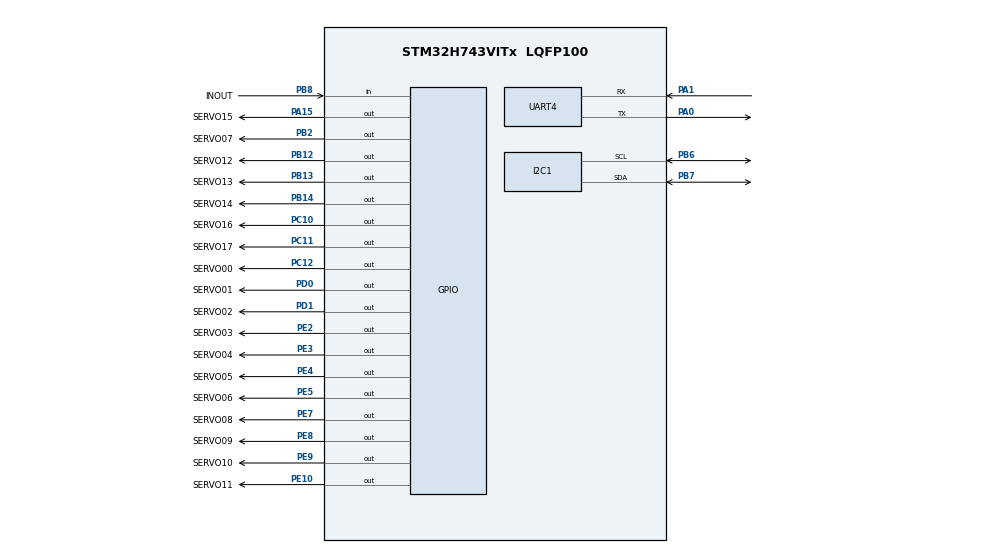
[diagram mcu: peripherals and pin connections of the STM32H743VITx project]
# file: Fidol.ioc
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Dma.Request0=UART4_RX
Dma.Request1=UART4_TX
Dma.UART4_RX.0.Direction=DMA_PERIPH_TO_MEMORY
Dma.UART4_RX.0.EventEnable=DISABLE
Dma.UART4_RX.0.FIFOMode=DMA_FIFOMODE_DISABLE
Dma.UART4_RX.0.Instance=DMA1_Stream0
Dma.UART4_RX.0.MemDataAlignment=DMA_MDATAALIGN_BYTE
Dma.UART4_RX.0.MemInc=DMA_MINC_ENABLE
Dma.UART4_RX.0.Mode=DMA_NORMAL
Dma.UART4_RX.0.PeriphDataAlignment=DMA_PDATAALIGN_BYTE
Dma.UART4_RX.0.PeriphInc=DMA_PINC_DISABLE
Dma.UART4_RX.0.Polarity=HAL_DMAMUX_REQ_GEN_RISING
Dma.UART4_RX.0.Priority=DMA_PRIORITY_LOW
Dma.UART4_RX.0.RequestNumber=1
Dma.UART4_RX.0.SignalID=NONE
Dma.UART4_RX.0.SyncEnable=DISABLE
Dma.UART4_RX.0.SyncPolarity=HAL_DMAMUX_SYNC_NO_EVENT
Dma.UART4_RX.0.SyncRequestNumber=1
Dma.UART4_RX.0.SyncSignalID=NONE
Dma.UART4_TX.1.Direction=DMA_MEMORY_TO_PERIPH
Dma.UART4_TX.1.EventEnable=DISABLE
Dma.UART4_TX.1.FIFOMode=DMA_FIFOMODE_DISABLE
Dma.UART4_TX.1.Instance=DMA1_Stream1
Dma.UART4_TX.1.MemDataAlignment=DMA_MDATAALIGN_BYTE
Dma.UART4_TX.1.MemInc=DMA_MINC_ENABLE
Dma.UART4_TX.1.Mode=DMA_NORMAL
Dma.UART4_TX.1.PeriphDataAlignment=DMA_PDATAALIGN_BYTE
Dma.UART4_TX.1.PeriphInc=DMA_PINC_DISABLE
Dma.UART4_TX.1.Polarity=HAL_DMAMUX_REQ_GEN_RISING
Dma.UART4_TX.1.Priority=DMA_PRIORITY_LOW
Dma.UART4_TX.1.RequestNumber=1
Dma.UART4_TX.1.SignalID=NONE
Dma.UART4_TX.1.SyncEnable=DISABLE
Dma.UART4_TX.1.SyncPolarity=HAL_DMAMUX_SYNC_NO_EVENT
Dma.UART4_TX.1.SyncRequestNumber=1
Dma.UART4_TX.1.SyncSignalID=NONE
I2C1.Timing=0x10C0ECFF
Mcu.Family=STM32H7
Mcu.Name=STM32H743VITx
Mcu.Package=LQFP100
NVIC.DMA1_Stream0_IRQn=true\:0\:0\:false\:true\:true\:1\:false\:true
NVIC.DMA1_Stream1_IRQn=true\:0\:0\:false\:true\:true\:2\:false\:true
NVIC.PriorityGroup=NVIC_PRIORITYGROUP_4
NVIC.TIM2_IRQn=true\:0\:0\:false\:true\:true\:4\:true\:true
NVIC.UART4_IRQn=true\:0\:0\:false\:true\:true\:3\:true\:true
PA0.Mode=Asynchronous
PA0.Signal=UART4_TX
PA1.Mode=Asynchronous
PA1.Signal=UART4_RX
PA13\ (JTMS/SWDIO).Mode=Trace_Asynchronous_SW
PA13\ (JTMS/SWDIO).Signal=DEBUG_JTMS-SWDIO
PA14\ (JTCK/SWCLK).Mode=Trace_Asynchronous_SW
PA14\ (JTCK/SWCLK).Signal=DEBUG_JTCK-SWCLK
PA15\ (JTDI).GPIO_Label=SERVO15
PA15\ (JTDI).Signal=GPIO_Output
PB12.GPIO_Label=SERVO12
PB12.Signal=GPIO_Output
PB13.GPIO_Label=SERVO13
PB13.Signal=GPIO_Output
PB14.GPIO_Label=SERVO14
PB14.Signal=GPIO_Output
PB2.GPIO_Label=SERVO07
PB2.Signal=GPIO_Output
PB3\ (JTDO/TRACESWO).Mode=Trace_Asynchronous_SW
PB3\ (JTDO/TRACESWO).Signal=DEBUG_JTDO-SWO
PB6.Mode=I2C
PB6.Signal=I2C1_SCL
PB7.Mode=I2C
PB7.Signal=I2C1_SDA
PB8.GPIO_Label=INOUT
PB8.Signal=GPIO_Input
PC10.GPIO_Label=SERVO16
PC10.Signal=GPIO_Output
PC11.GPIO_Label=SERVO17
PC11.Signal=GPIO_Output
PC12.GPIO_Label=SERVO00
PC12.Signal=GPIO_Output
PD0.GPIO_Label=SERVO01
PD0.Signal=GPIO_Output
PD1.GPIO_Label=SERVO02
PD1.Signal=GPIO_Output
PE10.GPIO_Label=SERVO11
PE10.Signal=GPIO_Output
PE2.GPIO_Label=SERVO03
PE2.Signal=GPIO_Output
PE3.GPIO_Label=SERVO04
PE3.Signal=GPIO_Output
PE4.GPIO_Label=SERVO05
PE4.Signal=GPIO_Output
PE5.GPIO_Label=SERVO06
PE5.Signal=GPIO_Output
PE7.GPIO_Label=SERVO08
PE7.Signal=GPIO_Output
PE8.GPIO_Label=SERVO09
PE8.Signal=GPIO_Output
PE9.GPIO_Label=SERVO10
PE9.Signal=GPIO_Output
PH0-OSC_IN\ (PH0).Mode=HSE-External-Clock-Source
PH0-OSC_IN\ (PH0).Signal=RCC_OSC_IN
ProjectManager.HeapSize=0x200
ProjectManager.StackSize=0x400
ProjectManager.TargetToolchain=STM32CubeIDE
RCC.ADCFreq_Value=48375000
RCC.APB1Freq_Value=100000000
RCC.APB2Freq_Value=100000000
RCC.APB3Freq_Value=100000000
RCC.APB4Freq_Value=100000000
RCC.CortexFreq_Value=400000000
RCC.D1PPRE=RCC_APB3_DIV2
RCC.D2PPRE1=RCC_APB1_DIV2
RCC.D2PPRE2=RCC_APB2_DIV2
RCC.D3PPRE=RCC_APB4_DIV2
RCC.DIVM1=3
RCC.DIVN1=100
RCC.DIVR1=5
RCC.HCLKFreq_Value=200000000
RCC.HPRE=RCC_HCLK_DIV2
RCC.HSE_VALUE=24000000
RCC.PLL2FRACN=0
RCC.PLL3FRACN=0
RCC.PLLFRACN=0
RCC.PLLSourceVirtual=RCC_PLLSOURCE_HSE
RCC.PWR_Regulator_Voltage_Scale=PWR_REGULATOR_VOLTAGE_SCALE0
RCC.SYSCLKFreq_VALUE=400000000
RCC.SYSCLKSource=RCC_SYSCLKSOURCE_PLLCLK
RCC.SupplySource=PWR_LDO_SUPPLY
RCC.USBFreq_Value=400000000
TIM2.Channel-PWM\ Generation1\ No\ Output=TIM_CHANNEL_1
TIM2.Channel-PWM\ Generation2\ No\ Output=TIM_CHANNEL_2
TIM2.Channel-PWM\ Generation3\ No\ Output=TIM_CHANNEL_3
TIM2.Period=2500
TIM2.Prescaler=199
VP_TIM2_VS_no_output1.Mode=PWM Generation1 No Output
VP_TIM2_VS_no_output2.Mode=PWM Generation2 No Output
VP_TIM2_VS_no_output3.Mode=PWM Generation3 No Output
board=custom

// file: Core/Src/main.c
/* USER CODE BEGIN Header */
/**
  ******************************************************************************
  * @file           : main.c
  * @brief          : Main program body
  ******************************************************************************
  * @attention
  *
  * <h2><center>&copy; Copyright (c) 2021 STMicroelectronics.
  * All rights reserved.</center></h2>
  *
  * This software component is licensed by ST under BSD 3-Clause license,
  * the "License"; You may not use this file except in compliance with the
  * License. You may obtain a copy of the License at:
  *                        opensource.org/licenses/BSD-3-Clause
  *
  ******************************************************************************
  */
/* USER CODE END Header */
#include "main.h"

/* USER CODE BEGIN Includes */
#include "EntryCPP.hpp"
/* USER CODE END Includes */

I2C_HandleTypeDef hi2c1;

TIM_HandleTypeDef htim2;

UART_HandleTypeDef huart4;
DMA_HandleTypeDef hdma_uart4_rx;
DMA_HandleTypeDef hdma_uart4_tx;

void SystemClock_Config(void);
static void MX_GPIO_Init(void);
static void MX_I2C1_Init(void);
static void MX_DMA_Init(void);
static void MX_TIM2_Init(void);
static void MX_UART4_Init(void);
static void MX_NVIC_Init(void);

int main(void)
{

  /* MCU Configuration--------------------------------------------------------*/

  /* Reset of all peripherals, Initializes the Flash interface and the Systick. */
  HAL_Init();

  /* Configure the system clock */
  SystemClock_Config();

  /* Initialize all configured peripherals */
  MX_GPIO_Init();
  MX_I2C1_Init();
  MX_DMA_Init();
  MX_TIM2_Init();
  MX_UART4_Init();

  /* Initialize interrupts */
  MX_NVIC_Init();

  /* Infinite loop */
  /* USER CODE BEGIN WHILE */
  main_cpp();
  while (1)
  {
    /* USER CODE END WHILE */

  }
}

void SystemClock_Config(void)
{
  RCC_OscInitTypeDef RCC_OscInitStruct = {0};
  RCC_ClkInitTypeDef RCC_ClkInitStruct = {0};

  /** Supply configuration update enable
  */
  HAL_PWREx_ConfigSupply(PWR_LDO_SUPPLY);
  /** Configure the main internal regulator output voltage
  */
  __HAL_PWR_VOLTAGESCALING_CONFIG(PWR_REGULATOR_VOLTAGE_SCALE0);

  while(!__HAL_PWR_GET_FLAG(PWR_FLAG_VOSRDY)) {}
  /** Initializes the RCC Oscillators according to the specified parameters
  * in the RCC_OscInitTypeDef structure.
  */
  RCC_OscInitStruct.OscillatorType = RCC_OSCILLATORTYPE_HSE;
  RCC_OscInitStruct.HSEState = RCC_HSE_BYPASS;
  RCC_OscInitStruct.PLL.PLLState = RCC_PLL_ON;
  RCC_OscInitStruct.PLL.PLLSource = RCC_PLLSOURCE_HSE;
  RCC_OscInitStruct.PLL.PLLM = 3;
  RCC_OscInitStruct.PLL.PLLN = 100;
  RCC_OscInitStruct.PLL.PLLP = 2;
  RCC_OscInitStruct.PLL.PLLQ = 2;
  RCC_OscInitStruct.PLL.PLLR = 5;
  RCC_OscInitStruct.PLL.PLLRGE = RCC_PLL1VCIRANGE_3;
  RCC_OscInitStruct.PLL.PLLVCOSEL = RCC_PLL1VCOWIDE;
  RCC_OscInitStruct.PLL.PLLFRACN = 0;
  if (HAL_RCC_OscConfig(&RCC_OscInitStruct) != HAL_OK)
  {
    Error_Handler();
  }
  /** Initializes the CPU, AHB and APB buses clocks
  */
  RCC_ClkInitStruct.ClockType = RCC_CLOCKTYPE_HCLK|RCC_CLOCKTYPE_SYSCLK
                              |RCC_CLOCKTYPE_PCLK1|RCC_CLOCKTYPE_PCLK2
                              |RCC_CLOCKTYPE_D3PCLK1|RCC_CLOCKTYPE_D1PCLK1;
  RCC_ClkInitStruct.SYSCLKSource = RCC_SYSCLKSOURCE_PLLCLK;
  RCC_ClkInitStruct.SYSCLKDivider = RCC_SYSCLK_DIV1;
  RCC_ClkInitStruct.AHBCLKDivider = RCC_HCLK_DIV2;
  RCC_ClkInitStruct.APB3CLKDivider = RCC_APB3_DIV2;
  RCC_ClkInitStruct.APB1CLKDivider = RCC_APB1_DIV2;
  RCC_ClkInitStruct.APB2CLKDivider = RCC_APB2_DIV2;
  RCC_ClkInitStruct.APB4CLKDivider = RCC_APB4_DIV2;

  if (HAL_RCC_ClockConfig(&RCC_ClkInitStruct, FLASH_LATENCY_2) != HAL_OK)
  {
    Error_Handler();
  }
}

/**
  * @brief NVIC Configuration.
  * @retval None
  */
static void MX_NVIC_Init(void)
{
  /* DMA1_Stream0_IRQn interrupt configuration */
  HAL_NVIC_SetPriority(DMA1_Stream0_IRQn, 0, 0);
  HAL_NVIC_EnableIRQ(DMA1_Stream0_IRQn);
  /* DMA1_Stream1_IRQn interrupt configuration */
  HAL_NVIC_SetPriority(DMA1_Stream1_IRQn, 0, 0);
  HAL_NVIC_EnableIRQ(DMA1_Stream1_IRQn);
  /* UART4_IRQn interrupt configuration */
  HAL_NVIC_SetPriority(UART4_IRQn, 0, 0);
  HAL_NVIC_EnableIRQ(UART4_IRQn);
  /* TIM2_IRQn interrupt configuration */
  HAL_NVIC_SetPriority(TIM2_IRQn, 0, 0);
  HAL_NVIC_EnableIRQ(TIM2_IRQn);
}

static void MX_I2C1_Init(void)
{

  hi2c1.Instance = I2C1;
  hi2c1.Init.Timing = 0x10C0ECFF;
  hi2c1.Init.OwnAddress1 = 0;
  hi2c1.Init.AddressingMode = I2C_ADDRESSINGMODE_7BIT;
  hi2c1.Init.DualAddressMode = I2C_DUALADDRESS_DISABLE;
  hi2c1.Init.OwnAddress2 = 0;
  hi2c1.Init.OwnAddress2Masks = I2C_OA2_NOMASK;
  hi2c1.Init.GeneralCallMode = I2C_GENERALCALL_DISABLE;
  hi2c1.Init.NoStretchMode = I2C_NOSTRETCH_DISABLE;
  if (HAL_I2C_Init(&hi2c1) != HAL_OK)
  {
    Error_Handler();
  }
  /** Configure Analogue filter
  */
  if (HAL_I2CEx_ConfigAnalogFilter(&hi2c1, I2C_ANALOGFILTER_ENABLE) != HAL_OK)
  {
    Error_Handler();
  }
  /** Configure Digital filter
  */
  if (HAL_I2CEx_ConfigDigitalFilter(&hi2c1, 0) != HAL_OK)
  {
    Error_Handler();
  }

}

static void MX_TIM2_Init(void)
{

  TIM_MasterConfigTypeDef sMasterConfig = {0};
  TIM_OC_InitTypeDef sConfigOC = {0};

  htim2.Instance = TIM2;
  htim2.Init.Prescaler = 199;
  htim2.Init.CounterMode = TIM_COUNTERMODE_UP;
  htim2.Init.Period = 2500;
  htim2.Init.ClockDivision = TIM_CLOCKDIVISION_DIV1;
  htim2.Init.AutoReloadPreload = TIM_AUTORELOAD_PRELOAD_DISABLE;
  if (HAL_TIM_PWM_Init(&htim2) != HAL_OK)
  {
    Error_Handler();
  }
  sMasterConfig.MasterOutputTrigger = TIM_TRGO_RESET;
  sMasterConfig.MasterSlaveMode = TIM_MASTERSLAVEMODE_DISABLE;
  if (HAL_TIMEx_MasterConfigSynchronization(&htim2, &sMasterConfig) != HAL_OK)
  {
    Error_Handler();
  }
  sConfigOC.OCMode = TIM_OCMODE_PWM1;
  sConfigOC.Pulse = 0;
  sConfigOC.OCPolarity = TIM_OCPOLARITY_HIGH;
  sConfigOC.OCFastMode = TIM_OCFAST_DISABLE;
  if (HAL_TIM_PWM_ConfigChannel(&htim2, &sConfigOC, TIM_CHANNEL_1) != HAL_OK)
  {
    Error_Handler();
  }
  if (HAL_TIM_PWM_ConfigChannel(&htim2, &sConfigOC, TIM_CHANNEL_2) != HAL_OK)
  {
    Error_Handler();
  }
  if (HAL_TIM_PWM_ConfigChannel(&htim2, &sConfigOC, TIM_CHANNEL_3) != HAL_OK)
  {
    Error_Handler();
  }

}

static void MX_UART4_Init(void)
{

  huart4.Instance = UART4;
  huart4.Init.BaudRate = 115200;
  huart4.Init.WordLength = UART_WORDLENGTH_8B;
  huart4.Init.StopBits = UART_STOPBITS_1;
  huart4.Init.Parity = UART_PARITY_NONE;
  huart4.Init.Mode = UART_MODE_TX_RX;
  huart4.Init.HwFlowCtl = UART_HWCONTROL_NONE;
  huart4.Init.OverSampling = UART_OVERSAMPLING_16;
  huart4.Init.OneBitSampling = UART_ONE_BIT_SAMPLE_DISABLE;
  huart4.Init.ClockPrescaler = UART_PRESCALER_DIV1;
  huart4.AdvancedInit.AdvFeatureInit = UART_ADVFEATURE_NO_INIT;
  if (HAL_UART_Init(&huart4) != HAL_OK)
  {
    Error_Handler();
  }
  if (HAL_UARTEx_SetTxFifoThreshold(&huart4, UART_TXFIFO_THRESHOLD_1_8) != HAL_OK)
  {
    Error_Handler();
  }
  if (HAL_UARTEx_SetRxFifoThreshold(&huart4, UART_RXFIFO_THRESHOLD_1_8) != HAL_OK)
  {
    Error_Handler();
  }
  if (HAL_UARTEx_DisableFifoMode(&huart4) != HAL_OK)
  {
    Error_Handler();
  }

}

static void MX_DMA_Init(void)
{

  /* DMA controller clock enable */
  __HAL_RCC_DMA1_CLK_ENABLE();

}

static void MX_GPIO_Init(void)
{
  GPIO_InitTypeDef GPIO_InitStruct = {0};

  /* GPIO Ports Clock Enable */
  __HAL_RCC_GPIOE_CLK_ENABLE();
  __HAL_RCC_GPIOH_CLK_ENABLE();
  __HAL_RCC_GPIOA_CLK_ENABLE();
  __HAL_RCC_GPIOB_CLK_ENABLE();
  __HAL_RCC_GPIOC_CLK_ENABLE();
  __HAL_RCC_GPIOD_CLK_ENABLE();

  /*Configure GPIO pin Output Level */
  HAL_GPIO_WritePin(GPIOE, SERVO03_Pin|SERVO04_Pin|SERVO05_Pin|SERVO06_Pin
                          |SERVO08_Pin|SERVO09_Pin|SERVO10_Pin|SERVO11_Pin, GPIO_PIN_RESET);

  /*Configure GPIO pin Output Level */
  HAL_GPIO_WritePin(GPIOB, SERVO07_Pin|SERVO12_Pin|SERVO13_Pin|SERVO14_Pin, GPIO_PIN_RESET);

  /*Configure GPIO pin Output Level */
  HAL_GPIO_WritePin(SERVO15_GPIO_Port, SERVO15_Pin, GPIO_PIN_RESET);

  /*Configure GPIO pin Output Level */
  HAL_GPIO_WritePin(GPIOC, SERVO16_Pin|SERVO17_Pin|SERVO00_Pin, GPIO_PIN_RESET);

  /*Configure GPIO pin Output Level */
  HAL_GPIO_WritePin(GPIOD, SERVO01_Pin|SERVO02_Pin, GPIO_PIN_RESET);

  /*Configure GPIO pins : SERVO03_Pin SERVO04_Pin SERVO05_Pin SERVO06_Pin
                           SERVO08_Pin SERVO09_Pin SERVO10_Pin SERVO11_Pin */
  GPIO_InitStruct.Pin = SERVO03_Pin|SERVO04_Pin|SERVO05_Pin|SERVO06_Pin
                          |SERVO08_Pin|SERVO09_Pin|SERVO10_Pin|SERVO11_Pin;
  GPIO_InitStruct.Mode = GPIO_MODE_OUTPUT_PP;
  GPIO_InitStruct.Pull = GPIO_NOPULL;
  GPIO_InitStruct.Speed = GPIO_SPEED_FREQ_LOW;
  HAL_GPIO_Init(GPIOE, &GPIO_InitStruct);

  /*Configure GPIO pins : SERVO07_Pin SERVO12_Pin SERVO13_Pin SERVO14_Pin */
  GPIO_InitStruct.Pin = SERVO07_Pin|SERVO12_Pin|SERVO13_Pin|SERVO14_Pin;
  GPIO_InitStruct.Mode = GPIO_MODE_OUTPUT_PP;
  GPIO_InitStruct.Pull = GPIO_NOPULL;
  GPIO_InitStruct.Speed = GPIO_SPEED_FREQ_LOW;
  HAL_GPIO_Init(GPIOB, &GPIO_InitStruct);

  /*Configure GPIO pin : SERVO15_Pin */
  GPIO_InitStruct.Pin = SERVO15_Pin;
  GPIO_InitStruct.Mode = GPIO_MODE_OUTPUT_PP;
  GPIO_InitStruct.Pull = GPIO_NOPULL;
  GPIO_InitStruct.Speed = GPIO_SPEED_FREQ_LOW;
  HAL_GPIO_Init(SERVO15_GPIO_Port, &GPIO_InitStruct);

  /*Configure GPIO pins : SERVO16_Pin SERVO17_Pin SERVO00_Pin */
  GPIO_InitStruct.Pin = SERVO16_Pin|SERVO17_Pin|SERVO00_Pin;
  GPIO_InitStruct.Mode = GPIO_MODE_OUTPUT_PP;
  GPIO_InitStruct.Pull = GPIO_NOPULL;
  GPIO_InitStruct.Speed = GPIO_SPEED_FREQ_LOW;
  HAL_GPIO_Init(GPIOC, &GPIO_InitStruct);

  /*Configure GPIO pins : SERVO01_Pin SERVO02_Pin */
  GPIO_InitStruct.Pin = SERVO01_Pin|SERVO02_Pin;
  GPIO_InitStruct.Mode = GPIO_MODE_OUTPUT_PP;
  GPIO_InitStruct.Pull = GPIO_NOPULL;
  GPIO_InitStruct.Speed = GPIO_SPEED_FREQ_LOW;
  HAL_GPIO_Init(GPIOD, &GPIO_InitStruct);

  /*Configure GPIO pin : INOUT_Pin */
  GPIO_InitStruct.Pin = INOUT_Pin;
  GPIO_InitStruct.Mode = GPIO_MODE_INPUT;
  GPIO_InitStruct.Pull = GPIO_NOPULL;
  HAL_GPIO_Init(INOUT_GPIO_Port, &GPIO_InitStruct);

}

void Error_Handler(void)
{
  __disable_irq();
  while (1)
  {
  }
}

/************************ (C) COPYRIGHT STMicroelectronics *****END OF FILE****/
